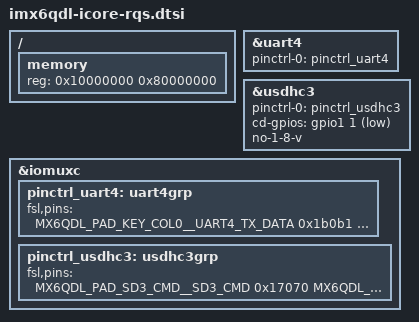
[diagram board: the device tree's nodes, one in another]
/*
 * Copyright (C) 2015 Amarula Solutions B.V.
 *
 * This file is dual-licensed: you can use it either under the terms
 * of the GPL or the X11 license, at your option. Note that this dual
 * licensing only applies to this file, and not this project as a
 * whole.
 *
 *  a) This file is free software; you can redistribute it and/or
 *     modify it under the terms of the GNU General Public License
 *     version 2 as published by the Free Software Foundation.
 *
 *     This file is distributed in the hope that it will be useful
 *     but WITHOUT ANY WARRANTY; without even the implied warranty of
 *     MERCHANTABILITY or FITNESS FOR A PARTICULAR PURPOSE.  See the
 *     GNU General Public License for more details.
 *
 * Or, alternatively
 *
 *  b) Permission is hereby granted, free of charge, to any person
 *     obtaining a copy of this software and associated documentation
 *     files (the "Software"), to deal in the Software without
 *     restriction, including without limitation the rights to use
 *     copy, modify, merge, publish, distribute, sublicense, and/or
 *     sell copies of the Software, and to permit persons to whom the
 *     Software is furnished to do so, subject to the following
 *     conditions:
 *
 *     The above copyright notice and this permission notice shall be
 *     included in all copies or substantial portions of the Software.
 *
 *     THE SOFTWARE IS PROVIDED , WITHOUT WARRANTY OF ANY KIND
 *     EXPRESS OR IMPLIED, INCLUDING BUT NOT LIMITED TO THE WARRANTIES
 *     OF MERCHANTABILITY, FITNESS FOR A PARTICULAR PURPOSE AND
 *     NONINFRINGEMENT. IN NO EVENT SHALL THE AUTHORS OR COPYRIGHT
 *     HOLDERS BE LIABLE FOR ANY CLAIM, DAMAGES OR OTHER LIABILITY
 *     WHETHER IN AN ACTION OF CONTRACT, TORT OR OTHERWISE, ARISING
 *     FROM, OUT OF OR IN CONNECTION WITH THE SOFTWARE OR THE USE OR
 *     OTHER DEALINGS IN THE SOFTWARE.
 */

#include <dt-bindings/gpio/gpio.h>
#include <dt-bindings/clock/imx6qdl-clock.h>

/ {
	memory {
		reg = <0x10000000 0x80000000>;
	};
};

&uart4 {
	pinctrl-names = "default";
	pinctrl-0 = <&pinctrl_uart4>;
	status = "okay";
};

&usdhc3 {
	pinctrl-names = "default";
	pinctrl-0 = <&pinctrl_usdhc3>;
	cd-gpios = <&gpio1 1 GPIO_ACTIVE_LOW>;
	no-1-8-v;
	status = "okay";
};

&iomuxc {
	pinctrl_uart4: uart4grp {
		fsl,pins = <
			MX6QDL_PAD_KEY_COL0__UART4_TX_DATA 0x1b0b1
			MX6QDL_PAD_KEY_ROW0__UART4_RX_DATA 0x1b0b1
		>;
	};

	pinctrl_usdhc3: usdhc3grp {
		fsl,pins = <
			MX6QDL_PAD_SD3_CMD__SD3_CMD    0x17070
			MX6QDL_PAD_SD3_CLK__SD3_CLK    0x10070
			MX6QDL_PAD_SD3_DAT0__SD3_DATA0 0x17070
			MX6QDL_PAD_SD3_DAT1__SD3_DATA1 0x17070
			MX6QDL_PAD_SD3_DAT2__SD3_DATA2 0x17070
			MX6QDL_PAD_SD3_DAT3__SD3_DATA3 0x17070
		>;
	};
};
